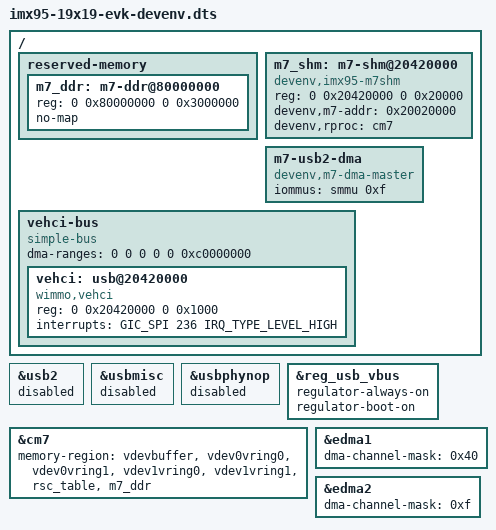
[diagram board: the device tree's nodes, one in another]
// SPDX-License-Identifier: (GPL-2.0+ OR MIT)
/*
 * imx95-devenv: i.MX95 19x19 LPDDR5 EVK with
 *  - the Cortex-M7 loaded and controlled from Linux via remoteproc (RPMsg over
 *    MU7, vrings + resource table at 0x88000000, as in the base EVK dts), and
 *  - 48 MiB of DDR at 0x80000000 reserved for Zephyr's imx95_evk/mimx9596/m7/ddr
 *    image (Zephyr uses 0x80000000 + 42 MiB). The region is added to the cm7
 *    memory-region list so remoteproc can load ELF segments there.
 *
 * Ethernet: ENETC0 (enetc_port0, RJ45 + RTL8211) stays a normal Linux PF.
 * VF1 of that port is handed to the M7 at runtime by m7-vf-handoff.service;
 * nothing VF-specific is needed in this device tree.
 */

#include "imx95-19x19-evk.dts"

/ {
	reserved-memory {
		m7_ddr: m7-ddr@80000000 {
			reg = <0 0x80000000 0 0x3000000>;
			no-map;
		};
	};

	/*
	 * Memory window shared with the M7: the upper 128 KiB of the M7 DTCM
	 * (M7 view 0x20020000, A55 view 0x20400000 + 128 KiB). Driver: m7shm.ko
	 * (linux/m7shm, /dev/m7shm). The Zephyr overlay has the M7 side; keep
	 * both in sync. TCM is not Linux RAM, so no reserved-memory entry.
	 */
	m7_shm: m7-shm@20420000 {
		compatible = "devenv,imx95-m7shm";
		reg = <0 0x20420000 0 0x20000>;
		devenv,m7-addr = <0x20020000>;
		devenv,rproc = <&cm7>;
	};

	/*
	 * USB2 (ChipIdea, Type-A port) belongs to the M7 (SM config mx95devenv:
	 * USB2 in LM1, so any A55 access faults). Linux has no USB2 node at all;
	 * this node only describes the controller's DMA stream (SID 0xf) so the
	 * SMMU knows it. No driver binds; m7-dma-handoff sets its IOMMU group to
	 * identity before the M7 starts, so the M7's USB DMA reaches its memory.
	 */
	m7-usb2-dma {
		compatible = "devenv,m7-dma-master";
		iommus = <&smmu 0xf>;
	};

	/*
	 * "Wimmo" virtual EHCI, emulated by the M7 in the first 4 KiB of the
	 * m7shm window (TCM). Linux drives it with its stock generic EHCI driver
	 * (ehci-platform), nothing else: no glue code.
	 *  - The register page only exists while the M7 runs, so the compatible
	 *    matches no driver; m7-vehci binds ehci-platform (driver_override)
	 *    once the M7 reports the controller ready and unbinds it before the
	 *    M7 stops.
	 *  - Interrupt: MSGINTR1, owned and raised/cleared by the M7 (A55 GIC SPI
	 *    236, level).
	 *  - DMA: dma-ranges keeps Linux's queue heads, qTDs and (bounced)
	 *    buffers below 0xC0000000, in DDR the M7 may access (SM config grants
	 *    0x90000000-0xDFFFFFFF). The limit also becomes Linux's ZONE_DMA
	 *    (arm64 takes the lowest dma-ranges in the tree): it must end below
	 *    the CMA area (0xC3000000+), or CMA spans two zones and is not
	 *    activated (seen: 0xE0000000 broke Weston's buffer allocations).
	 *    swiotlb lands below it too.
	 * On a PCIe endpoint the same M7 code sits behind a BAR, an MSI and an
	 * outbound window, with the host's stock ehci-pci.
	 */
	vehci-bus {
		compatible = "simple-bus";
		#address-cells = <2>;
		#size-cells = <2>;
		ranges;
		dma-ranges = <0 0 0 0 0 0xc0000000>;

		vehci: usb@20420000 {
			compatible = "wimmo,vehci";
			reg = <0 0x20420000 0 0x1000>;
			interrupts = <GIC_SPI 236 IRQ_TYPE_LEVEL_HIGH>;
		};
	};
};

/* Owned by the M7, see m7-usb2-dma above */
&usb2 {
	status = "disabled";
};

&usbmisc {
	status = "disabled";
};

&usbphynop {
	status = "disabled";
};

/*
 * VBUS of the USB2 Type-A port (GPIO expander on I2C7, owned by Linux). With
 * USB2 gone from Linux nothing would consume this regulator and Linux would
 * switch the port's 5 V off at boot; keep it on for the M7's USB host.
 */
&reg_usb_vbus {
	regulator-always-on;
	regulator-boot-on;
};

&cm7 {
	memory-region = <&vdevbuffer>, <&vdev0vring0>, <&vdev0vring1>,
			<&vdev1vring0>, <&vdev1vring1>, <&rsc_table>, <&m7_ddr>;
};

/*
 * eDMA channels owned by the M7 in the SM config (mx95devenv / mx95evkrpmsg):
 * EDMA1_CH6 and EDMA2_CH2_3. Linux must not touch them: probing those channels
 * raises an SError and panics the kernel at boot (seen on hardware 2026-11-16
 * in fsl_edma_chan_mux). NXP's imx95-19x19-evk-rpmsg.dts disables edma1/edma2
 * completely; masking only the M7's channels keeps DMA for Linux peripherals.
 * Verified on the board: the kernel boots with these masks.
 */
&edma1 {
	dma-channel-mask = <0x40>;	/* ch6 */
};

&edma2 {
	dma-channel-mask = <0xf>;	/* ch0-1 (imx95.dtsi default) + ch2-3 */
};
